VERSION ""

NS_ :

BS_:

BU_:

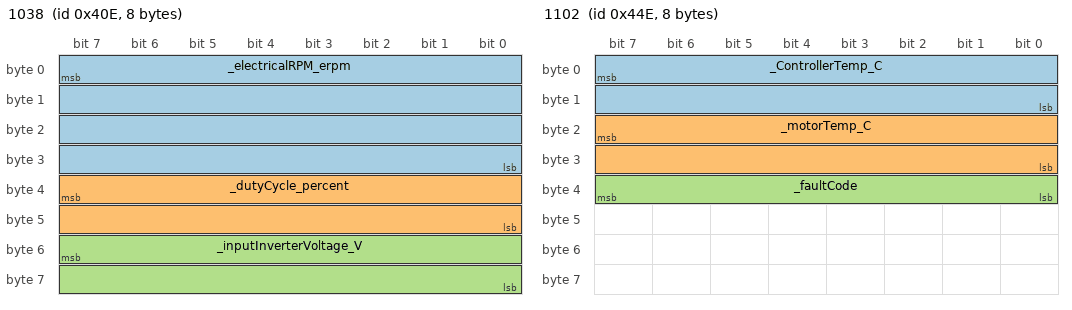
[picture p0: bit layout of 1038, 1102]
BO_ 1038 1038: 8 Vector__XXX
 SG_ _electricalRPM_erpm : 7|32@0+ (1,0) [0|0] "angular_speed:rpm" Vector__XXX
 SG_ _dutyCycle_percent : 39|16@0- (0.1,0) [0|0] "fraction:%" Vector__XXX
 SG_ _inputInverterVoltage_V : 55|16@0- (1,0) [0|0] "voltage:V" Vector__XXX

BO_ 1070 1070: 8 Vector__XXX
 SG_ _motorCurrentPeakToPeak_A : 7|16@0- (0.1,0) [0|0] "current:A" Vector__XXX
 SG_ _batteryCurrent_A : 23|16@0- (0.1,0) [0|0] "current:A" Vector__XXX

BO_ 1102 1102: 8 Vector__XXX
 SG_ _ControllerTemp_C : 7|16@0- (0.1,0) [0|0] "temperature:C" Vector__XXX
 SG_ _motorTemp_C : 23|16@0- (0.1,0) [0|0] "temperature:C" Vector__XXX
 SG_ _faultCode : 39|8@0+ (1,0) [0|0] "unitless:" Vector__XXX

BO_ 1134 1134: 8 Vector__XXX
 SG_ _idPeakToPeak_A : 7|32@0- (0.01,0) [0|0] "current:A" Vector__XXX
 SG_ _iqPeakToPeak_A : 39|32@0- (0.01,0) [0|0] "current:A" Vector__XXX

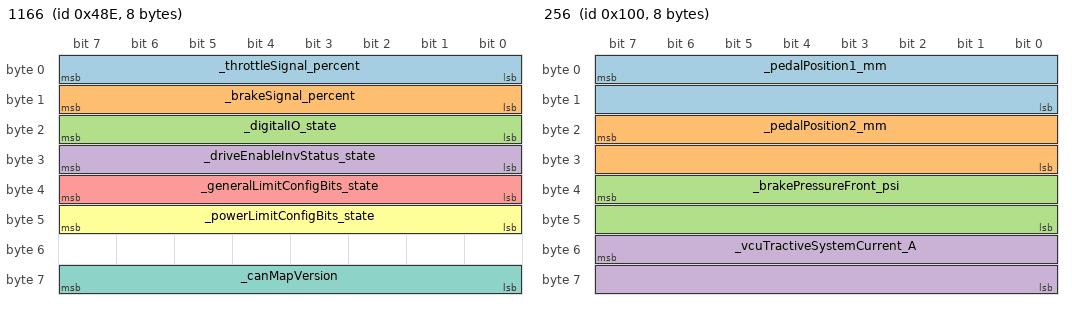
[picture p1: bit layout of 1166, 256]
BO_ 1166 1166: 8 Vector__XXX
 SG_ _throttleSignal_percent : 7|8@0+ (1,0) [0|0] "fraction:%" Vector__XXX
 SG_ _brakeSignal_percent : 15|8@0+ (1,0) [0|0] "fraction:%" Vector__XXX
 SG_ _digitalIO_state : 23|8@0+ (1,0) [0|0] "unitless:" Vector__XXX
 SG_ _driveEnableInvStatus_state : 31|8@0+ (1,0) [0|0] "unitless:" Vector__XXX
 SG_ _generalLimitConfigBits_state : 39|8@0+ (1,0) [0|0] "unitless:" Vector__XXX
 SG_ _powerLimitConfigBits_state : 47|8@0+ (1,0) [0|0] "unitless:" Vector__XXX
 SG_ _canMapVersion : 63|8@0+ (1,0) [0|0] "unitless:" Vector__XXX

BO_ 46 46: 8 Vector__XXX
 SG_ _desiredInvCurrentPeakToPeak_A_0 : 7|16@0- (0.1,0) [0|0] "current:A" Vector__XXX

BO_ 270 270: 8 Vector__XXX
 SG_ _maxCurrentLimitPeakToPeak_A : 7|16@0- (0.1,0) [0|0] "current:A" Vector__XXX

BO_ 398 398: 8 Vector__XXX
 SG_ _driveEnable_state : 7|8@0+ (1,0) [0|0] "current:A" Vector__XXX

BO_ 256 256: 8 Vector__XXX
 SG_ _pedalPosition1_mm : 7|16@0- (0.00610500611,0) [0|0] "distance:mm" Vector__XXX
 SG_ _pedalPosition2_mm : 23|16@0- (0.00610500611,0) [0|0] "distance:mm" Vector__XXX
 SG_ _brakePressureFront_psi : 39|16@0- (0.488400488,0) [0|0] "pressure:psi" Vector__XXX
 SG_ _vcuTractiveSystemCurrent_A : 55|16@0- (0.00914627595,-18.727) [0|0] "current:A" Vector__XXX

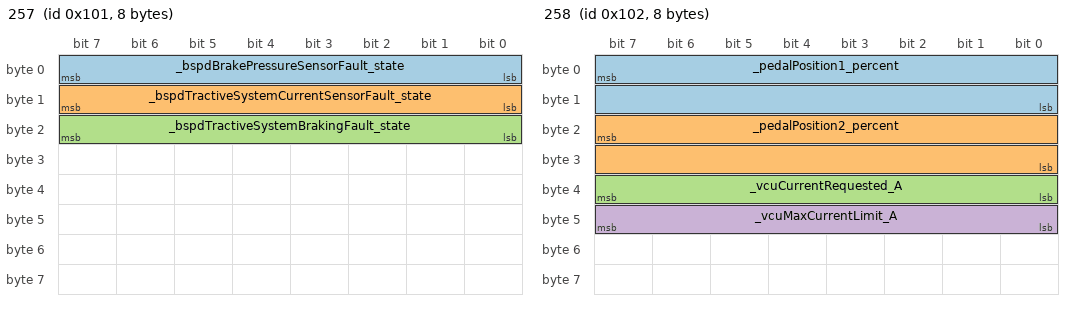
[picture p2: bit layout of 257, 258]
BO_ 257 257: 8 Vector__XXX
 SG_ _bspdBrakePressureSensorFault_state : 7|8@0+ (1,0) [0|0] "unitless:" Vector__XXX
 SG_ _bspdTractiveSystemCurrentSensorFault_state : 15|8@0+ (1,0) [0|0] "unitless:" Vector__XXX
 SG_ _bspdTractiveSystemBrakingFault_state : 23|8@0+ (1,0) [0|0] "unitless:" Vector__XXX

BO_ 258 258: 8 Vector__XXX
 SG_ _pedalPosition1_percent : 7|16@0- (0.1,0) [0|0] "fraction:%" Vector__XXX
 SG_ _pedalPosition2_percent : 23|16@0- (0.1,0) [0|0] "fraction:%" Vector__XXX
 SG_ _vcuCurrentRequested_A : 39|8@0- (1,0) [0|0] "torque:N.m" Vector__XXX
 SG_ _vcuMaxCurrentLimit_A : 47|8@0- (1,0) [0|0] "current:A" Vector__XXX

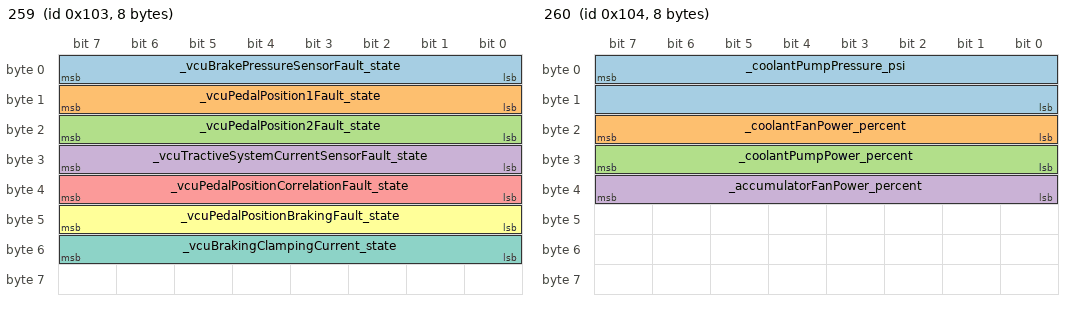
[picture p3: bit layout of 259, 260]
BO_ 259 259: 8 Vector__XXX
 SG_ _vcuBrakePressureSensorFault_state : 7|8@0+ (1,0) [0|0] "unitless:" Vector__XXX
 SG_ _vcuPedalPosition1Fault_state : 15|8@0+ (1,0) [0|0] "unitless:" Vector__XXX
 SG_ _vcuPedalPosition2Fault_state : 23|8@0+ (1,0) [0|0] "unitless:" Vector__XXX
 SG_ _vcuTractiveSystemCurrentSensorFault_state : 31|8@0+ (1,0) [0|0] "unitless:" Vector__XXX
 SG_ _vcuPedalPositionCorrelationFault_state : 39|8@0+ (1,0) [0|0] "unitless:" Vector__XXX
 SG_ _vcuPedalPositionBrakingFault_state : 47|8@0+ (1,0) [0|0] "unitless:" Vector__XXX
 SG_ _vcuBrakingClampingCurrent_state : 55|8@0+ (1,0) [0|0] "unitless:" Vector__XXX

BO_ 260 260: 8 Vector__XXX
 SG_ _coolantPumpPressure_psi : 7|16@0- (0.0244200244,0) [0|0] "pressure:psi" Vector__XXX
 SG_ _coolantFanPower_percent : 23|8@0+ (1,0) [0|0] "fraction:%" Vector__XXX
 SG_ _coolantPumpPower_percent : 31|8@0+ (1,0) [0|0] "fraction:%" Vector__XXX
 SG_ _accumulatorFanPower_percent : 39|8@0+ (1,0) [0|0] "fraction:%" Vector__XXX

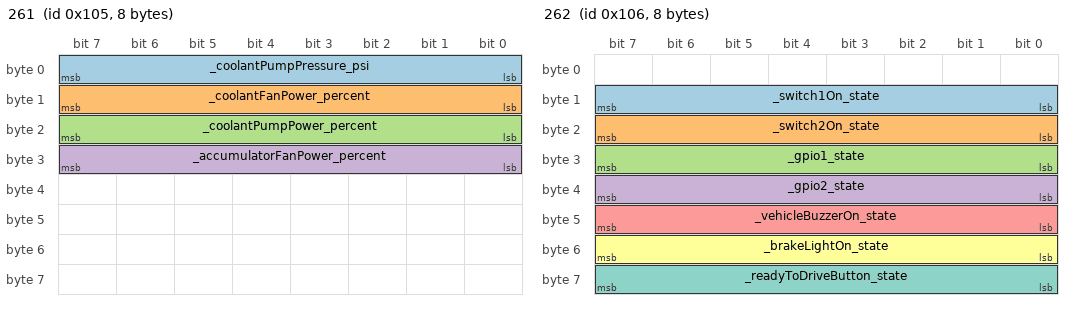
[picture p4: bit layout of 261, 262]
BO_ 261 261: 8 Vector__XXX
 SG_ _coolantPumpPressure_psi : 7|8@0- (0.0244200244,0) [0|0] "pressure:psi" Vector__XXX
 SG_ _coolantFanPower_percent : 15|8@0+ (1,0) [0|0] "fraction:%" Vector__XXX
 SG_ _coolantPumpPower_percent : 23|8@0+ (1,0) [0|0] "fraction:%" Vector__XXX
 SG_ _accumulatorFanPower_percent : 31|8@0+ (1,0) [0|0] "fraction:%" Vector__XXX

BO_ 262 262: 8 Vector__XXX
 SG_ _switch1On_state : 15|8@0+ (1,0) [0|0] "unitless:" Vector__XXX
 SG_ _switch2On_state : 23|8@0+ (1,0) [0|0] "unitless:" Vector__XXX
 SG_ _gpio1_state : 31|8@0+ (1,0) [0|0] "unitless:" Vector__XXX
 SG_ _gpio2_state : 39|8@0+ (1,0) [0|0] "unitless:" Vector__XXX
 SG_ _vehicleBuzzerOn_state : 47|8@0+ (1,0) [0|0] "unitless:" Vector__XXX
 SG_ _brakeLightOn_state : 55|8@0+ (1,0) [0|0] "unitless:" Vector__XXX
 SG_ _readyToDriveButton_state : 63|8@0+ (1,0) [0|0] "unitless:" Vector__XXX

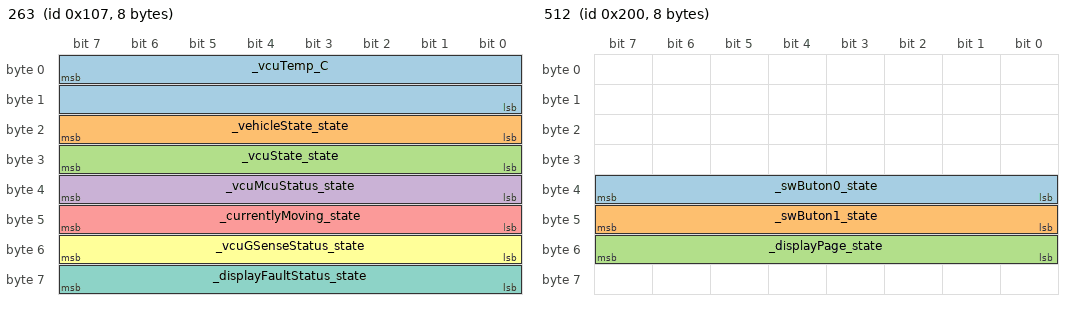
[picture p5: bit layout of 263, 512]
BO_ 263 263: 8 Vector__XXX
 SG_ _vcuTemp_C : 7|16@0- (0.1,0) [0|0] "temperature:C" Vector__XXX
 SG_ _vehicleState_state : 23|8@0+ (1,0) [0|0] "unitless:" Vector__XXX
 SG_ _vcuState_state : 31|8@0+ (1,0) [0|0] "unitless:" Vector__XXX
 SG_ _vcuMcuStatus_state : 39|8@0+ (1,0) [0|0] "unitless:" Vector__XXX
 SG_ _currentlyMoving_state : 47|8@0+ (1,0) [0|0] "unitless:" Vector__XXX
 SG_ _vcuGSenseStatus_state : 55|8@0+ (1,0) [0|0] "unitless:" Vector__XXX
 SG_ _displayFaultStatus_state : 63|8@0+ (1,0) [0|0] "unitless:" Vector__XXX

BO_ 512 512: 8 Vector__XXX
 SG_ _swButon0_state : 39|8@0+ (1,0) [0|0] "unitless:" Vector__XXX
 SG_ _swButon1_state : 47|8@0+ (1,0) [0|0] "unitless:" Vector__XXX
 SG_ _displayPage_state : 55|8@0+ (1,0) [0|0] "unitless:" Vector__XXX

BO_ 513 513: 8 Vector__XXX
 SG_ _swButon2_state : 23|8@0+ (1,0) [0|0] "unitless:" Vector__XXX
 SG_ _swButon3_state : 31|8@0+ (1,0) [0|0] "unitless:" Vector__XXX
 SG_ _swButon4_state : 39|8@0+ (1,0) [0|0] "unitless:" Vector__XXX
 SG_ _swButon5_state : 47|8@0+ (1,0) [0|0] "unitless:" Vector__XXX
 SG_ _swDial_a_ul : 55|8@0+ (1,0) [0|0] "unitless:" Vector__XXX
 SG_ _swDial_b_ul : 55|8@0+ (1,0) [0|0] "unitless:" Vector__XXX

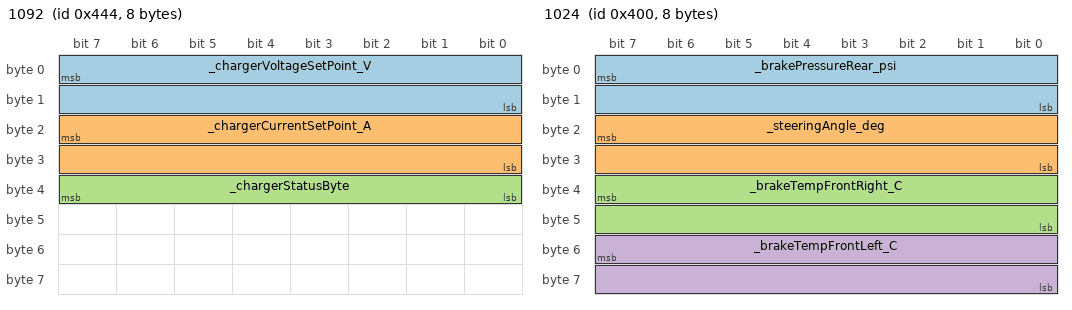
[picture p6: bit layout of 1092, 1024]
BO_ 1092 1092: 8 Vector__XXX
 SG_ _chargerVoltageSetPoint_V : 7|16@0- (0.1,0) [0|0] "voltage:V" Vector__XXX
 SG_ _chargerCurrentSetPoint_A : 23|16@0- (0.1,0) [0|0] "current:A" Vector__XXX
 SG_ _chargerStatusByte : 39|8@0+ (1,0) [0|0] "unitless:" Vector__XXX

BO_ 1024 1024: 8 Vector__XXX
 SG_ _brakePressureRear_psi : 7|16@0- (0.488400488,0) [0|0] "pressure:psi" Vector__XXX
 SG_ _steeringAngle_deg : 23|16@0- (0.0879120879,0) [0|0] "angle:deg" Vector__XXX
 SG_ _brakeTempFrontRight_C : 39|16@0- (0.195360195,0) [0|0] "temperature:C" Vector__XXX
 SG_ _brakeTempFrontLeft_C : 55|16@0- (0.195360195,0) [0|0] "temperature:C" Vector__XXX

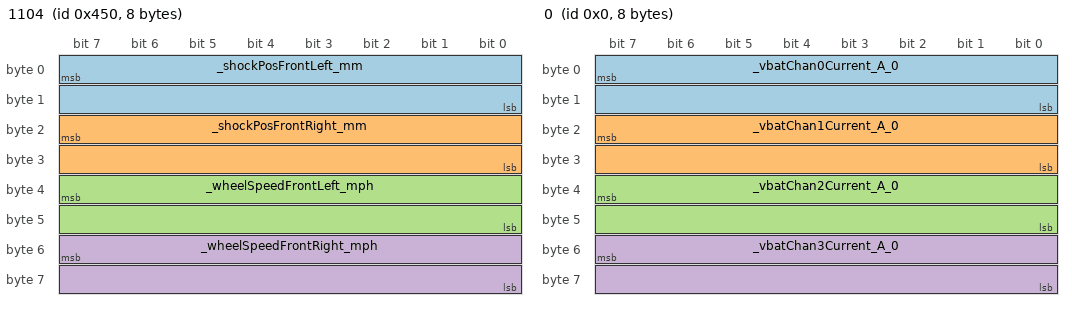
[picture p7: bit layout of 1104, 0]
BO_ 1104 1104: 8 Vector__XXX
 SG_ _shockPosFrontLeft_mm : 7|16@0- (0.00610500611,0) [0|0] "distance:mm" Vector__XXX
 SG_ _shockPosFrontRight_mm : 23|16@0- (0.00610500611,0) [0|0] "distance:mm" Vector__XXX
 SG_ _wheelSpeedFrontLeft_mph : 39|16@0- (0.002288853283971548,0) [0|0] "speed:mph" Vector__XXX
 SG_ _wheelSpeedFrontRight_mph : 55|16@0- (0.002288853283971548,0) [0|0] "speed:mph" Vector__XXX

BO_ 1105 1105: 8 Vector__XXX
 SG_ _pittoTubePressure_psi : 7|16@0- (0.01,0) [0|0] "pressure:psi" Vector__XXX

BO_ 0 0: 8 Vector__XXX
 SG_ _vbatChan0Current_A_0 : 7|16@0- (0.00741391941,0) [0|0] "voltage:V" Vector__XXX
 SG_ _vbatChan1Current_A_0 : 23|16@0- (0.00741391941,0) [0|0] "voltage:V" Vector__XXX
 SG_ _vbatChan2Current_A_0 : 39|16@0- (0.00741391941,0) [0|0] "voltage:V" Vector__XXX
 SG_ _vbatChan3Current_A_0 : 55|16@0- (0.00741391941,0) [0|0] "voltage:V" Vector__XXX

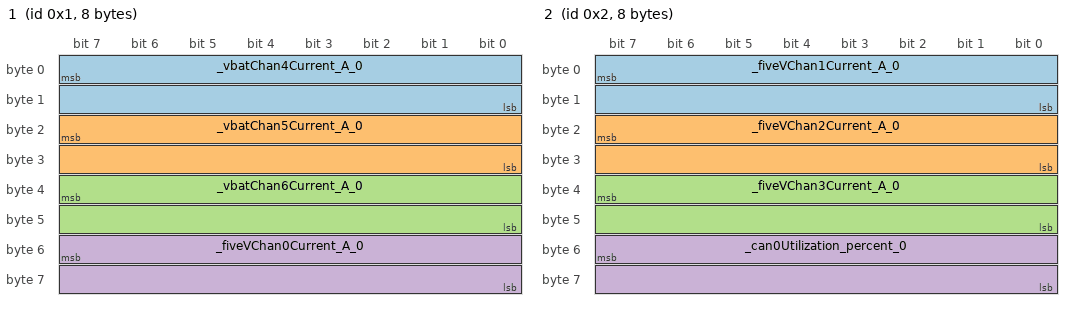
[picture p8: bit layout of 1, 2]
BO_ 1 1: 8 Vector__XXX
 SG_ _vbatChan4Current_A_0 : 7|16@0- (0.00741391941,0) [0|0] "voltage:V" Vector__XXX
 SG_ _vbatChan5Current_A_0 : 23|16@0- (0.00741391941,0) [0|0] "voltage:V" Vector__XXX
 SG_ _vbatChan6Current_A_0 : 39|16@0- (0.00741391941,0) [0|0] "voltage:V" Vector__XXX
 SG_ _fiveVChan0Current_A_0 : 55|16@0- (0.00196141636,0) [0|0] "voltage:V" Vector__XXX

BO_ 2 2: 8 Vector__XXX
 SG_ _fiveVChan1Current_A_0 : 7|16@0- (0.00196141636,0) [0|0] "voltage:V" Vector__XXX
 SG_ _fiveVChan2Current_A_0 : 23|16@0- (0.00196141636,0) [0|0] "voltage:V" Vector__XXX
 SG_ _fiveVChan3Current_A_0 : 39|16@0- (0.00196141636,0) [0|0] "voltage:V" Vector__XXX
 SG_ _can0Utilization_percent_0 : 55|16@0- (0.1,0) [0|0] "fraction:%" Vector__XXX

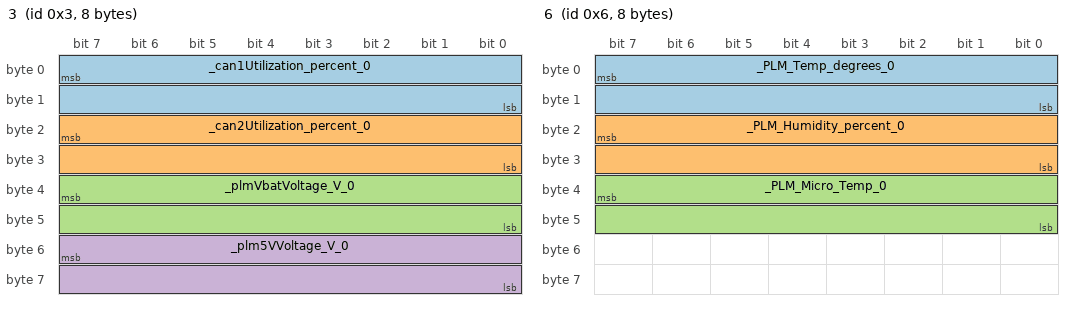
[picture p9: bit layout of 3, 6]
BO_ 3 3: 8 Vector__XXX
 SG_ _can1Utilization_percent_0 : 7|16@0- (0.1,0) [0|0] "fraction:%" Vector__XXX
 SG_ _can2Utilization_percent_0 : 23|16@0- (0.1,0) [0|0] "fraction:%" Vector__XXX
 SG_ _plmVbatVoltage_V_0 : 39|16@0- (0.00506178266,0) [0|0] "voltage:V" Vector__XXX
 SG_ _plm5VVoltage_V_0 : 55|16@0- (0.00195457875,0) [0|0] "voltage:V" Vector__XXX

BO_ 4 4: 8 Vector__XXX
 SG_ _packetsLogged_ul_0 : 7|32@0+ (1,0) [0|0] "unitless:" Vector__XXX
 SG_ _packetsDropped_ul_0 : 39|32@0+ (1,0) [0|0] "unitless:" Vector__XXX

BO_ 5 5: 8 Vector__XXX
 SG_ _storageBufferFill_percent_0 : 7|16@0- (0.1,0) [0|0] "fraction:%" Vector__XXX
 SG_ _telemetryBufferFill_percent_0 : 23|16@0- (0.1,0) [0|0] "fraction:%" Vector__XXX

BO_ 6 6: 8 Vector__XXX
 SG_ _PLM_Temp_degrees_0 : 7|16@0- (0.002518,-40) [0|0] "temperature:C" Vector__XXX
 SG_ _PLM_Humidity_percent_0 : 23|16@0- (0.024414,0) [0|0] "fraction:%" Vector__XXX
 SG_ _PLM_Micro_Temp_0 : 39|16@0- (0.024414,0) [0|0] "fraction:%" Vector__XXX

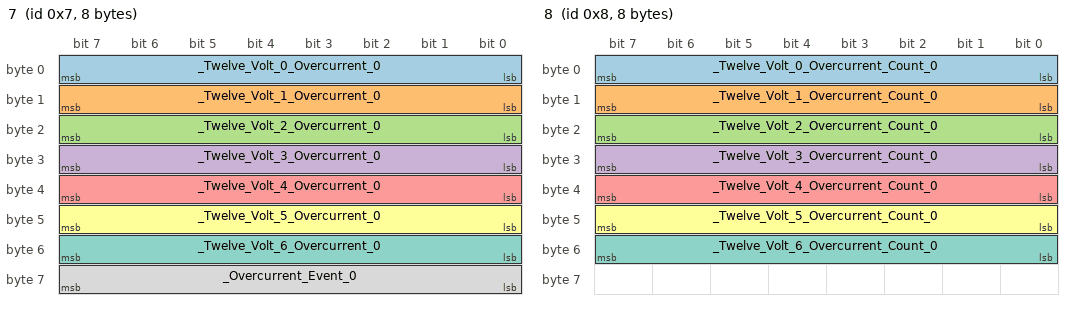
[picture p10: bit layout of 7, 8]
BO_ 7 7: 8 Vector__XXX
 SG_ _Twelve_Volt_0_Overcurrent_0 : 7|8@0+ (1,0) [0|0] "unitless:" Vector__XXX
 SG_ _Twelve_Volt_1_Overcurrent_0 : 15|8@0+ (1,0) [0|0] "unitless:" Vector__XXX
 SG_ _Twelve_Volt_2_Overcurrent_0 : 23|8@0+ (1,0) [0|0] "unitless:" Vector__XXX
 SG_ _Twelve_Volt_3_Overcurrent_0 : 31|8@0+ (1,0) [0|0] "unitless:" Vector__XXX
 SG_ _Twelve_Volt_4_Overcurrent_0 : 39|8@0+ (1,0) [0|0] "unitless:" Vector__XXX
 SG_ _Twelve_Volt_5_Overcurrent_0 : 47|8@0+ (1,0) [0|0] "unitless:" Vector__XXX
 SG_ _Twelve_Volt_6_Overcurrent_0 : 55|8@0+ (1,0) [0|0] "unitless:" Vector__XXX
 SG_ _Overcurrent_Event_0 : 63|8@0+ (1,0) [0|0] "unitless:" Vector__XXX

BO_ 8 8: 8 Vector__XXX
 SG_ _Twelve_Volt_0_Overcurrent_Count_0 : 7|8@0+ (1,0) [0|0] "unitless:" Vector__XXX
 SG_ _Twelve_Volt_1_Overcurrent_Count_0 : 15|8@0+ (1,0) [0|0] "unitless:" Vector__XXX
 SG_ _Twelve_Volt_2_Overcurrent_Count_0 : 23|8@0+ (1,0) [0|0] "unitless:" Vector__XXX
 SG_ _Twelve_Volt_3_Overcurrent_Count_0 : 31|8@0+ (1,0) [0|0] "unitless:" Vector__XXX
 SG_ _Twelve_Volt_4_Overcurrent_Count_0 : 39|8@0+ (1,0) [0|0] "unitless:" Vector__XXX
 SG_ _Twelve_Volt_5_Overcurrent_Count_0 : 47|8@0+ (1,0) [0|0] "unitless:" Vector__XXX
 SG_ _Twelve_Volt_6_Overcurrent_Count_0 : 55|8@0+ (1,0) [0|0] "unitless:" Vector__XXX

BO_ 229 229: 8 Vector__XXX
 SG_ _lapBeaconRaw_ul_0 : 7|24@0- (1,0) [0|0] "unitless:" Vector__XXX

BO_ 272 272: 8 Vector__XXX
 SG_ _lapBeacon_ul : 7|8@0- (1,0) [0|0] "unitless:" Vector__XXX
